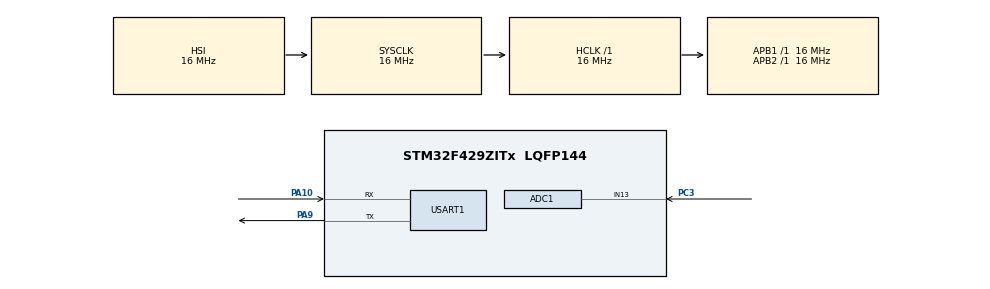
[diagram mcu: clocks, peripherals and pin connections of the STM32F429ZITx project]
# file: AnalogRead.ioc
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ADC1.Channel-4\#ChannelRegularConversion=ADC_CHANNEL_13
ADC1.ClockPrescaler=ADC_CLOCK_SYNC_PCLK_DIV2
ADC1.ContinuousConvMode=ENABLE
ADC1.DMAContinuousRequests=ENABLE
ADC1.NbrOfConversionFlag=1
ADC1.Rank-4\#ChannelRegularConversion=1
ADC1.Resolution=ADC_RESOLUTION_12B
ADC1.SamplingTime-4\#ChannelRegularConversion=ADC_SAMPLETIME_3CYCLES
ADC1.master=1
Dma.ADC1.0.Direction=DMA_PERIPH_TO_MEMORY
Dma.ADC1.0.FIFOMode=DMA_FIFOMODE_ENABLE
Dma.ADC1.0.FIFOThreshold=DMA_FIFO_THRESHOLD_HALFFULL
Dma.ADC1.0.Instance=DMA2_Stream0
Dma.ADC1.0.MemBurst=DMA_MBURST_SINGLE
Dma.ADC1.0.MemDataAlignment=DMA_MDATAALIGN_HALFWORD
Dma.ADC1.0.MemInc=DMA_MINC_ENABLE
Dma.ADC1.0.Mode=DMA_CIRCULAR
Dma.ADC1.0.PeriphBurst=DMA_PBURST_SINGLE
Dma.ADC1.0.PeriphDataAlignment=DMA_PDATAALIGN_HALFWORD
Dma.ADC1.0.PeriphInc=DMA_PINC_DISABLE
Dma.ADC1.0.Priority=DMA_PRIORITY_LOW
Dma.Request0=ADC1
Mcu.Family=STM32F4
Mcu.Name=STM32F429ZITx
Mcu.Package=LQFP144
NVIC.ADC_IRQn=true\:0\:0\:false\:false\:true\:true\:true\:true
NVIC.DMA2_Stream0_IRQn=true\:0\:0\:false\:false\:true\:false\:true\:true
NVIC.PriorityGroup=NVIC_PRIORITYGROUP_4
PA10.Mode=Asynchronous
PA10.Signal=USART1_RX
PA9.Mode=Asynchronous
PA9.Signal=USART1_TX
PC3.Signal=ADCx_IN13
ProjectManager.HeapSize=0x200
ProjectManager.StackSize=0x400
ProjectManager.TargetToolchain=STM32CubeIDE
RCC.AHBFreq_Value=16000000
RCC.APB1Freq_Value=16000000
RCC.APB2Freq_Value=16000000
RCC.CortexFreq_Value=16000000
RCC.HSE_VALUE=25000000
RCC.HSI_VALUE=16000000
RCC.LSE_VALUE=32768
RCC.SYSCLKFreq_VALUE=16000000
RCC.VCOOutputFreq_Value=192000000
SH.ADCx_IN13.0=ADC1_IN13,IN13
USART1.VirtualMode=VM_ASYNC
board=custom

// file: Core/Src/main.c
/* USER CODE BEGIN Header */
/**
  ******************************************************************************
  * @file           : main.c
  * @brief          : Main program body
  ******************************************************************************
  * @attention
  *
  * Copyright (c) 2025 STMicroelectronics.
  * All rights reserved.
  *
  * This software is licensed under terms that can be found in the LICENSE file
  * in the root directory of this software component.
  * If no LICENSE file comes with this software, it is provided AS-IS.
  *
  ******************************************************************************
  */
/* USER CODE END Header */
#include "main.h"

ADC_HandleTypeDef hadc1;
DMA_HandleTypeDef hdma_adc1;

UART_HandleTypeDef huart1;

/* USER CODE BEGIN PV */

/**
 * @brief Giá trị 12-bit đọc được từ cảm biến, thông qua ADC. Vậy giá trị trong khoảng [0,4095]
 * @note  - giá trị số 12-bit, trong phạm vi [0,4095]
 *        - Vẫn áp dụng được với DMA, vì DMA sẽ tự động align về 32-bit.
 * @see   HAL_ADC_Start(), HAL_ADC_PollForConversion(), HAL_ADC_GetValue()
 */
uint16_t sensor_value;

/**
 * @brief Bộ đệm dữ liệu để soạn thông diệp và gửi về máy tinh, thông qua UART
 * @note  The buffer, used to draft the message and then, send it to PC by UART
 * @see   huart1
 */
char uart_buffer[50];
/* USER CODE END PV */

void SystemClock_Config(void);
static void MX_GPIO_Init(void);
static void MX_DMA_Init(void);
static void MX_ADC1_Init(void);
static void MX_USART1_UART_Init(void);

int main(void)
{

  /* MCU Configuration--------------------------------------------------------*/

  /* Reset of all peripherals, Initializes the Flash interface and the Systick. */
  HAL_Init();

  /* Configure the system clock */
  SystemClock_Config();

  /* Initialize all configured peripherals */
  MX_GPIO_Init();
  MX_DMA_Init();
  MX_ADC1_Init();
  MX_USART1_UART_Init();
  /* USER CODE BEGIN 2 */
#if defined(MY_ADC_DMA)
  /// Kích hoạt ADC DMA request sau lần truyền cuối cùng (Chế độ Single-ADC) và kích hoạt thiết bị ngoại vi ADC,
  /// trong đó sensor_value là địa chỉ đích, sẽ được DMA tự động copy dữ liệu từ thiết bị ngoại vi vào đó.
  /// CHÚ Ý:
  ///   - Tham số 2: là ĐỊA CHỈ của buffer chứa kết quả, do ADC chuyển đổi và được DMAC copy vào.
  ///   - Tham số 3: là số phần tử của buffer, không phải là số byte. Ví dụ uint16_t buffer[20] thì tham số này là 20.
  HAL_ADC_Start_DMA(&hadc1, (uint32_t *)(&sensor_value), 1);

#elif defined(MY_ADC_INTERRUPT)
  /// Yêu cầu ADC thực hiện chuyển đổi dữ liệu Anglog --> Digital ở kênh đã chỉ định, và dùng Interrupt.
  /// Lưu ý: Với thăm dò polling thì dùng hàm HAL_ADC_Start(), với thăm dò bằng ngắt thì dùng HAL_ADC_Start_IT()
  HAL_ADC_Start_IT(&hadc1);
#endif
  /* USER CODE END 2 */

  /* Infinite loop */
  /* USER CODE BEGIN WHILE */
  while (1)
  {

#ifdef MY_ADC_POLLING
	  /// Yêu cầu ADC thực hiện chuyển đổi dữ liệu Anglog --> Digital ở kênh đã chỉ định
	  /// Lưu ý: Với thăm dò polling thì dùng hàm HAL_ADC_Start(), với thăm dò bằng ngắt thì dùng HAL_ADC_Start_IT()
	  HAL_ADC_Start(&hadc1);

	  /// Quá trình chuyển đổi đòi hòi thời gian (tốc độ lấy mẫu).
	  /// Bởi vậy, cần đợi một chút cho tới khi thực hiện xong, nhưng không đợi quá Timeout 20ms.
	  /// ==> hàm Blocking, thực hiện vòng lặp đợi dữ liệu kiểu Polling.
	  /// ADC sẽ dừng sau khi đọc xong dữ liệu, nên phải gọi lại HAL_ADC_Start.
	  HAL_ADC_PollForConversion(&hadc1, 20);

	  /// Lúc này dữ liệu đã sẵn sàng trong bộ ADC. Lấy về và lưu vào biến chỉ định.
	  sensor_value = HAL_ADC_GetValue(&hadc1);

	  /// Truyền về máy tính để tiện giám sát số liệu
	  sprintf(uart_buffer, "%s: %d\r\n", UART_PROMT, sensor_value);
	  HAL_UART_Transmit(&huart1, (uint8_t *)uart_buffer, strlen(uart_buffer), HAL_MAX_DELAY);
	  /// Đợi một chút. Nhưng không được phép sử dụng khi dùng ngắt, vì hàm này blocking, xung đột.

#endif

    /* USER CODE END WHILE */

    /* USER CODE BEGIN 3 */
	  HAL_Delay(200);
  }
  /* USER CODE END 3 */
}

void SystemClock_Config(void)
{
  RCC_OscInitTypeDef RCC_OscInitStruct = {0};
  RCC_ClkInitTypeDef RCC_ClkInitStruct = {0};

  /** Configure the main internal regulator output voltage
  */
  __HAL_RCC_PWR_CLK_ENABLE();
  __HAL_PWR_VOLTAGESCALING_CONFIG(PWR_REGULATOR_VOLTAGE_SCALE3);

  /** Initializes the RCC Oscillators according to the specified parameters
  * in the RCC_OscInitTypeDef structure.
  */
  RCC_OscInitStruct.OscillatorType = RCC_OSCILLATORTYPE_HSI;
  RCC_OscInitStruct.HSIState = RCC_HSI_ON;
  RCC_OscInitStruct.HSICalibrationValue = RCC_HSICALIBRATION_DEFAULT;
  RCC_OscInitStruct.PLL.PLLState = RCC_PLL_NONE;
  if (HAL_RCC_OscConfig(&RCC_OscInitStruct) != HAL_OK)
  {
    Error_Handler();
  }

  /** Initializes the CPU, AHB and APB buses clocks
  */
  RCC_ClkInitStruct.ClockType = RCC_CLOCKTYPE_HCLK|RCC_CLOCKTYPE_SYSCLK
                              |RCC_CLOCKTYPE_PCLK1|RCC_CLOCKTYPE_PCLK2;
  RCC_ClkInitStruct.SYSCLKSource = RCC_SYSCLKSOURCE_HSI;
  RCC_ClkInitStruct.AHBCLKDivider = RCC_SYSCLK_DIV1;
  RCC_ClkInitStruct.APB1CLKDivider = RCC_HCLK_DIV1;
  RCC_ClkInitStruct.APB2CLKDivider = RCC_HCLK_DIV1;

  if (HAL_RCC_ClockConfig(&RCC_ClkInitStruct, FLASH_LATENCY_0) != HAL_OK)
  {
    Error_Handler();
  }
}

static void MX_ADC1_Init(void)
{

  ADC_ChannelConfTypeDef sConfig = {0};

  /** Configure the global features of the ADC (Clock, Resolution, Data Alignment and number of conversion)
  */
  hadc1.Instance = ADC1;
  hadc1.Init.ClockPrescaler = ADC_CLOCK_SYNC_PCLK_DIV2;
  hadc1.Init.Resolution = ADC_RESOLUTION_12B;
  hadc1.Init.ScanConvMode = DISABLE;
  hadc1.Init.ContinuousConvMode = ENABLE;
  hadc1.Init.DiscontinuousConvMode = DISABLE;
  hadc1.Init.ExternalTrigConvEdge = ADC_EXTERNALTRIGCONVEDGE_NONE;
  hadc1.Init.ExternalTrigConv = ADC_SOFTWARE_START;
  hadc1.Init.DataAlign = ADC_DATAALIGN_RIGHT;
  hadc1.Init.NbrOfConversion = 1;
  hadc1.Init.DMAContinuousRequests = ENABLE;
  hadc1.Init.EOCSelection = ADC_EOC_SINGLE_CONV;
  if (HAL_ADC_Init(&hadc1) != HAL_OK)
  {
    Error_Handler();
  }

  /** Configure for the selected ADC regular channel its corresponding rank in the sequencer and its sample time.
  */
  sConfig.Channel = ADC_CHANNEL_13;
  sConfig.Rank = 1;
  sConfig.SamplingTime = ADC_SAMPLETIME_3CYCLES;
  if (HAL_ADC_ConfigChannel(&hadc1, &sConfig) != HAL_OK)
  {
    Error_Handler();
  }

}

static void MX_USART1_UART_Init(void)
{

  huart1.Instance = USART1;
  huart1.Init.BaudRate = 115200;
  huart1.Init.WordLength = UART_WORDLENGTH_8B;
  huart1.Init.StopBits = UART_STOPBITS_1;
  huart1.Init.Parity = UART_PARITY_NONE;
  huart1.Init.Mode = UART_MODE_TX_RX;
  huart1.Init.HwFlowCtl = UART_HWCONTROL_NONE;
  huart1.Init.OverSampling = UART_OVERSAMPLING_16;
  if (HAL_UART_Init(&huart1) != HAL_OK)
  {
    Error_Handler();
  }

}

static void MX_DMA_Init(void)
{

  /* DMA controller clock enable */
  __HAL_RCC_DMA2_CLK_ENABLE();

  /* DMA interrupt init */
  /* DMA2_Stream0_IRQn interrupt configuration */
  HAL_NVIC_SetPriority(DMA2_Stream0_IRQn, 0, 0);
  HAL_NVIC_EnableIRQ(DMA2_Stream0_IRQn);

}

static void MX_GPIO_Init(void)
{

  /* GPIO Ports Clock Enable */
  __HAL_RCC_GPIOC_CLK_ENABLE();
  __HAL_RCC_GPIOA_CLK_ENABLE();

}

/* USER CODE BEGIN 4 */
#if defined(MY_ADC_INTERRUPT) || defined(MY_ADC_DMA)
/**
 * @brief  Hàm sự kiện được gọi khi dữ liệu đã sẵn sàng trong ADC (với ngắt) hoặc dữ liệu đã sẵn sàng trong biến variable (với DMC)
 * @detail Trường hợp 1: chỉ Ngắt-Không DMA: Hàm sự kiện được gọi sau khi
 *         ADC chuyển đổi thành công dữ liệu và dữ liệu mới nằm trên module ADC.
 *         Nếu ADC tiếp tục chuyển đổi thì dữ liệu trong ADC sẽ bị ghi đè liên tiếp.
 *         Rất cả các ADC khi có ngắt đều triệu gọi hàm này.
 *         Vì vậy nếu phần mềm dùng nhiều ADC, ví dụ joystick với 2 ADC theo 2 trục x,y,
 *         thì phải kiểm tra nguồn ADC nào tạo ra bằng (hadc->Instance == ADC1)
 *         Trường hợp 2: Ngắt và DMA:  Hàm sự kiện được gọi sau khi ADC chuyển đổi thành công dữ liệu
 *         và DMA hoàn tất copy dữ liệu vào đich
 * @note   ADC thực hiện với đồng hồ 48MHz, nhanh hơn nhiều so với core 12Mhz,
 * @remark Cách để tạo khung của hàm này là:
 * 		   - Ở cửa sổ Project Explorer, mở thư mục Drivers\STM32F4xx_HAL_Driver\Src
 *         - Mở file stm32f4xx_hal_adc.c
 *         - Tìm file hoặc trong cửa sổ Outline và copy khai báo hàm vào đây
 *         - Xong. Đây là dạng hàm abtract, nên chỉ cần viết đè là xong.
 */
void HAL_ADC_ConvCpltCallback(ADC_HandleTypeDef *hadc){
	if(hadc->Instance == ADC1) {
#if defined(MY_ADC_INTERRUPT)
		// Khi ngắt triệu gọi hàm này, dữ liệu đã sẵn sàng và chỉ việc lấy về
		sensor_value = HAL_ADC_GetValue(&hadc1);
#endif
		/// Truyền về máy tính để tiện giám sát số liệu
		sprintf(uart_buffer, "%s:: %d\r\n", UART_PROMT, sensor_value);
		HAL_UART_Transmit(&huart1, (uint8_t *)uart_buffer, strlen(uart_buffer), HAL_MAX_DELAY);
#if defined(MY_ADC_INTERRUPT)
		// Gửi dữ liệu xong thì kích hoạt lại ngắt, nhắm tránh việc gửi UART quá chậm, xung đột với ngắt dữ liệu sẵn sàng từ ADC.
		HAL_ADC_Start_IT(&hadc1);
#endif
	}
}
#endif

/* USER CODE END 4 */

void Error_Handler(void)
{
  __disable_irq();
  while (1)
  {
  }
}
